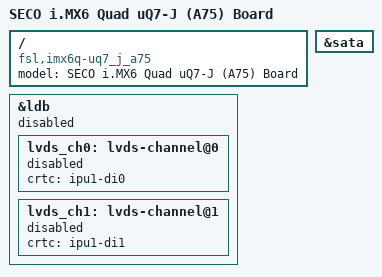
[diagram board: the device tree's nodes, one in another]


/dts-v1/;

#include "imx6q.dtsi"
#include "imx6qdl-seco_uQ7_J_A75.dtsi"
#include "imx6qdl-seco_lvds_display.dtsi"

/ {
	model = "SECO i.MX6 Quad uQ7-J (A75) Board";
	compatible = "fsl,imx6q-uq7_j_a75", "fsl,imx6q";
};

&ldb {
	status = "disabled";

	lvds_ch0: lvds-channel@0 {
		status = "disabled";
		crtc   = "ipu1-di0";
	};

	lvds_ch1: lvds-channel@1 {
		status = "disabled";
		crtc   = "ipu1-di1";
	};
};


&sata {
	status = "okay";
};
